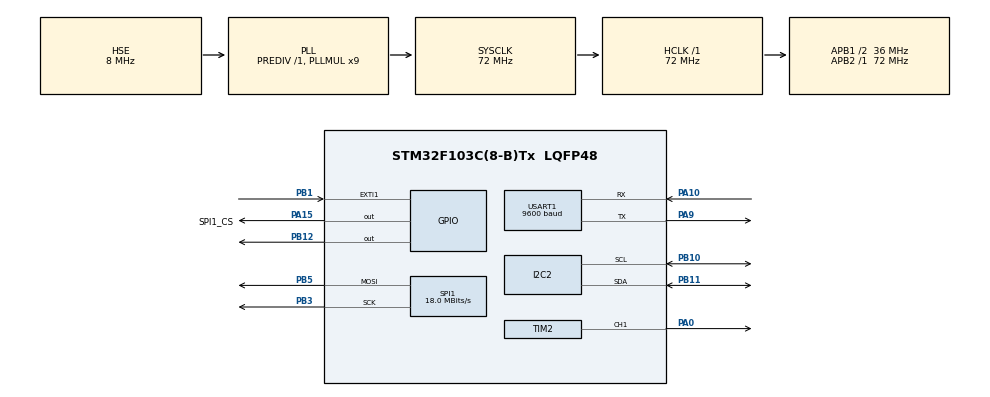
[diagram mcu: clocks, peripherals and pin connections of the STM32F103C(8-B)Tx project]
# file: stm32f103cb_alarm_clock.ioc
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Dma.Request0=TIM2_CH1
Dma.TIM2_CH1.0.Direction=DMA_MEMORY_TO_PERIPH
Dma.TIM2_CH1.0.Instance=DMA1_Channel5
Dma.TIM2_CH1.0.MemDataAlignment=DMA_MDATAALIGN_WORD
Dma.TIM2_CH1.0.MemInc=DMA_MINC_ENABLE
Dma.TIM2_CH1.0.Mode=DMA_NORMAL
Dma.TIM2_CH1.0.PeriphDataAlignment=DMA_PDATAALIGN_WORD
Dma.TIM2_CH1.0.PeriphInc=DMA_PINC_DISABLE
Dma.TIM2_CH1.0.Priority=DMA_PRIORITY_VERY_HIGH
Mcu.Family=STM32F1
Mcu.Name=STM32F103C(8-B)Tx
Mcu.Package=LQFP48
NVIC.DMA1_Channel5_IRQn=true\:0\:0\:false\:false\:true\:false\:true\:true
NVIC.EXTI1_IRQn=true\:0\:0\:false\:false\:true\:true\:true\:true
NVIC.PriorityGroup=NVIC_PRIORITYGROUP_4
NVIC.TIM3_IRQn=true\:0\:0\:false\:false\:true\:true\:true\:true
PA0-WKUP.Signal=S_TIM2_CH1_ETR
PA10.Mode=Asynchronous
PA10.Signal=USART1_RX
PA13.Mode=Serial_Wire
PA13.Signal=SYS_JTMS-SWDIO
PA14.Mode=Serial_Wire
PA14.Signal=SYS_JTCK-SWCLK
PA15.GPIO_Label=SPI1_CS
PA15.Signal=GPIO_Output
PA9.Mode=Asynchronous
PA9.Signal=USART1_TX
PB1.Signal=GPXTI1
PB10.Mode=I2C
PB10.Signal=I2C2_SCL
PB11.Mode=I2C
PB11.Signal=I2C2_SDA
PB12.Signal=GPIO_Output
PB3.Mode=TX_Only_Simplex_Unidirect_Master
PB3.Signal=SPI1_SCK
PB5.Mode=TX_Only_Simplex_Unidirect_Master
PB5.Signal=SPI1_MOSI
PC14-OSC32_IN.Mode=LSE-External-Oscillator
PC14-OSC32_IN.Signal=RCC_OSC32_IN
PC15-OSC32_OUT.Mode=LSE-External-Oscillator
PC15-OSC32_OUT.Signal=RCC_OSC32_OUT
PD0-OSC_IN.Mode=HSE-External-Oscillator
PD0-OSC_IN.Signal=RCC_OSC_IN
PD1-OSC_OUT.Mode=HSE-External-Oscillator
PD1-OSC_OUT.Signal=RCC_OSC_OUT
ProjectManager.HeapSize=0x200
ProjectManager.StackSize=0x400
ProjectManager.TargetToolchain=STM32CubeIDE
RCC.AHBFreq_Value=72000000
RCC.APB1CLKDivider=RCC_HCLK_DIV2
RCC.APB1Freq_Value=36000000
RCC.APB1TimFreq_Value=72000000
RCC.APB2Freq_Value=72000000
RCC.APB2TimFreq_Value=72000000
RCC.HCLKFreq_Value=72000000
RCC.PLLMUL=RCC_PLL_MUL9
RCC.PLLSourceVirtual=RCC_PLLSOURCE_HSE
RCC.SYSCLKFreq_VALUE=72000000
RCC.SYSCLKSource=RCC_SYSCLKSOURCE_PLLCLK
RCC.USBFreq_Value=72000000
SH.S_TIM2_CH1_ETR.0=TIM2_CH1,PWM Generation1 CH1
SPI1.BaudRatePrescaler=SPI_BAUDRATEPRESCALER_4
SPI1.CLKPhase=SPI_PHASE_2EDGE
SPI1.CLKPolarity=SPI_POLARITY_HIGH
SPI1.CalculateBaudRate=18.0 MBits/s
SPI1.DataSize=SPI_DATASIZE_8BIT
SPI1.Direction=SPI_DIRECTION_2LINES
SPI1.FirstBit=SPI_FIRSTBIT_MSB
SPI1.Mode=SPI_MODE_MASTER
SPI1.VirtualType=VM_MASTER
TIM1.Period=256
TIM1.Prescaler=1
TIM2.Channel-PWM\ Generation1\ CH1=TIM_CHANNEL_1
TIM2.Period=90-1
TIM3.Period=35999
TIM3.Prescaler=1
USART1.BaudRate=9600
USART1.Mode=MODE_TX_RX
USART1.VirtualMode=VM_ASYNC
VP_RTC_VS_RTC_Activate.Mode=RTC_Enabled
VP_RTC_VS_RTC_Calendar.Mode=RTC_Calendar
VP_TIM1_VS_ClockSourceINT.Mode=Internal
VP_TIM2_VS_ClockSourceINT.Mode=Internal
VP_TIM3_VS_ClockSourceINT.Mode=Internal
board=custom

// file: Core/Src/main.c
/* USER CODE BEGIN Header */
/**
  ******************************************************************************
  * @file           : main.c
  * @brief          : Main program body
  ******************************************************************************
  * @attention
  *
  * Copyright (c) 2025 STMicroelectronics.
  * All rights reserved.
  *
  * This software is licensed under terms that can be found in the LICENSE file
  * in the root directory of this software component.
  * If no LICENSE file comes with this software, it is provided AS-IS.
  *
  ******************************************************************************
  */
/* USER CODE END Header */
#include "main.h"

/* USER CODE BEGIN Includes */
#include "application.h"
/* USER CODE END Includes */

I2C_HandleTypeDef hi2c2;

RTC_HandleTypeDef hrtc;

SPI_HandleTypeDef hspi1;

TIM_HandleTypeDef htim1;
TIM_HandleTypeDef htim2;
TIM_HandleTypeDef htim3;
DMA_HandleTypeDef hdma_tim2_ch1;

UART_HandleTypeDef huart1;

void SystemClock_Config(void);
static void MX_GPIO_Init(void);
static void MX_DMA_Init(void);
static void MX_SPI1_Init(void);
static void MX_TIM2_Init(void);
static void MX_TIM1_Init(void);
static void MX_TIM3_Init(void);
static void MX_USART1_UART_Init(void);
static void MX_RTC_Init(void);
static void MX_I2C2_Init(void);

int main(void)
{

  /* MCU Configuration--------------------------------------------------------*/

  /* Reset of all peripherals, Initializes the Flash interface and the Systick. */
  HAL_Init();

  /* Configure the system clock */
  SystemClock_Config();

  /* Initialize all configured peripherals */
  MX_GPIO_Init();
  MX_DMA_Init();
  MX_SPI1_Init();
  MX_TIM2_Init();
  MX_TIM1_Init();
  MX_TIM3_Init();
  MX_USART1_UART_Init();
  MX_RTC_Init();
  MX_I2C2_Init();
  /* USER CODE BEGIN 2 */
  Application.init();
  /* USER CODE END 2 */

  /* Infinite loop */
  /* USER CODE BEGIN WHILE */
  while (1)
  {
	Application.run();
    /* USER CODE END WHILE */

  }
}

void SystemClock_Config(void)
{
  RCC_OscInitTypeDef RCC_OscInitStruct = {0};
  RCC_ClkInitTypeDef RCC_ClkInitStruct = {0};
  RCC_PeriphCLKInitTypeDef PeriphClkInit = {0};

  /** Initializes the RCC Oscillators according to the specified parameters
  * in the RCC_OscInitTypeDef structure.
  */
  RCC_OscInitStruct.OscillatorType = RCC_OSCILLATORTYPE_LSI|RCC_OSCILLATORTYPE_HSE;
  RCC_OscInitStruct.HSEState = RCC_HSE_ON;
  RCC_OscInitStruct.HSEPredivValue = RCC_HSE_PREDIV_DIV1;
  RCC_OscInitStruct.HSIState = RCC_HSI_ON;
  RCC_OscInitStruct.LSIState = RCC_LSI_ON;
  RCC_OscInitStruct.PLL.PLLState = RCC_PLL_ON;
  RCC_OscInitStruct.PLL.PLLSource = RCC_PLLSOURCE_HSE;
  RCC_OscInitStruct.PLL.PLLMUL = RCC_PLL_MUL9;
  if (HAL_RCC_OscConfig(&RCC_OscInitStruct) != HAL_OK)
  {
    Error_Handler();
  }

  /** Initializes the CPU, AHB and APB buses clocks
  */
  RCC_ClkInitStruct.ClockType = RCC_CLOCKTYPE_HCLK|RCC_CLOCKTYPE_SYSCLK
                              |RCC_CLOCKTYPE_PCLK1|RCC_CLOCKTYPE_PCLK2;
  RCC_ClkInitStruct.SYSCLKSource = RCC_SYSCLKSOURCE_PLLCLK;
  RCC_ClkInitStruct.AHBCLKDivider = RCC_SYSCLK_DIV1;
  RCC_ClkInitStruct.APB1CLKDivider = RCC_HCLK_DIV2;
  RCC_ClkInitStruct.APB2CLKDivider = RCC_HCLK_DIV1;

  if (HAL_RCC_ClockConfig(&RCC_ClkInitStruct, FLASH_LATENCY_2) != HAL_OK)
  {
    Error_Handler();
  }
  PeriphClkInit.PeriphClockSelection = RCC_PERIPHCLK_RTC;
  PeriphClkInit.RTCClockSelection = RCC_RTCCLKSOURCE_LSI;
  if (HAL_RCCEx_PeriphCLKConfig(&PeriphClkInit) != HAL_OK)
  {
    Error_Handler();
  }
}

static void MX_I2C2_Init(void)
{

  hi2c2.Instance = I2C2;
  hi2c2.Init.ClockSpeed = 100000;
  hi2c2.Init.DutyCycle = I2C_DUTYCYCLE_2;
  hi2c2.Init.OwnAddress1 = 0;
  hi2c2.Init.AddressingMode = I2C_ADDRESSINGMODE_7BIT;
  hi2c2.Init.DualAddressMode = I2C_DUALADDRESS_DISABLE;
  hi2c2.Init.OwnAddress2 = 0;
  hi2c2.Init.GeneralCallMode = I2C_GENERALCALL_DISABLE;
  hi2c2.Init.NoStretchMode = I2C_NOSTRETCH_DISABLE;
  if (HAL_I2C_Init(&hi2c2) != HAL_OK)
  {
    Error_Handler();
  }

}

static void MX_RTC_Init(void)
{

  RTC_TimeTypeDef sTime = {0};
  RTC_DateTypeDef DateToUpdate = {0};

  /** Initialize RTC Only
  */
  hrtc.Instance = RTC;
  hrtc.Init.AsynchPrediv = RTC_AUTO_1_SECOND;
  hrtc.Init.OutPut = RTC_OUTPUTSOURCE_ALARM;
  if (HAL_RTC_Init(&hrtc) != HAL_OK)
  {
    Error_Handler();
  }

  /** Initialize RTC and set the Time and Date
  */
  sTime.Hours = 0x0;
  sTime.Minutes = 0x0;
  sTime.Seconds = 0x0;

  if (HAL_RTC_SetTime(&hrtc, &sTime, RTC_FORMAT_BCD) != HAL_OK)
  {
    Error_Handler();
  }
  DateToUpdate.WeekDay = RTC_WEEKDAY_MONDAY;
  DateToUpdate.Month = RTC_MONTH_JANUARY;
  DateToUpdate.Date = 0x1;
  DateToUpdate.Year = 0x0;

  if (HAL_RTC_SetDate(&hrtc, &DateToUpdate, RTC_FORMAT_BCD) != HAL_OK)
  {
    Error_Handler();
  }

}

static void MX_SPI1_Init(void)
{

  /* SPI1 parameter configuration*/
  hspi1.Instance = SPI1;
  hspi1.Init.Mode = SPI_MODE_MASTER;
  hspi1.Init.Direction = SPI_DIRECTION_2LINES;
  hspi1.Init.DataSize = SPI_DATASIZE_8BIT;
  hspi1.Init.CLKPolarity = SPI_POLARITY_HIGH;
  hspi1.Init.CLKPhase = SPI_PHASE_2EDGE;
  hspi1.Init.NSS = SPI_NSS_SOFT;
  hspi1.Init.BaudRatePrescaler = SPI_BAUDRATEPRESCALER_4;
  hspi1.Init.FirstBit = SPI_FIRSTBIT_MSB;
  hspi1.Init.TIMode = SPI_TIMODE_DISABLE;
  hspi1.Init.CRCCalculation = SPI_CRCCALCULATION_DISABLE;
  hspi1.Init.CRCPolynomial = 10;
  if (HAL_SPI_Init(&hspi1) != HAL_OK)
  {
    Error_Handler();
  }

}

static void MX_TIM1_Init(void)
{

  TIM_ClockConfigTypeDef sClockSourceConfig = {0};
  TIM_MasterConfigTypeDef sMasterConfig = {0};

  htim1.Instance = TIM1;
  htim1.Init.Prescaler = 1;
  htim1.Init.CounterMode = TIM_COUNTERMODE_UP;
  htim1.Init.Period = 256;
  htim1.Init.ClockDivision = TIM_CLOCKDIVISION_DIV1;
  htim1.Init.RepetitionCounter = 0;
  htim1.Init.AutoReloadPreload = TIM_AUTORELOAD_PRELOAD_DISABLE;
  if (HAL_TIM_Base_Init(&htim1) != HAL_OK)
  {
    Error_Handler();
  }
  sClockSourceConfig.ClockSource = TIM_CLOCKSOURCE_INTERNAL;
  if (HAL_TIM_ConfigClockSource(&htim1, &sClockSourceConfig) != HAL_OK)
  {
    Error_Handler();
  }
  sMasterConfig.MasterOutputTrigger = TIM_TRGO_RESET;
  sMasterConfig.MasterSlaveMode = TIM_MASTERSLAVEMODE_DISABLE;
  if (HAL_TIMEx_MasterConfigSynchronization(&htim1, &sMasterConfig) != HAL_OK)
  {
    Error_Handler();
  }

}

static void MX_TIM2_Init(void)
{

  TIM_ClockConfigTypeDef sClockSourceConfig = {0};
  TIM_MasterConfigTypeDef sMasterConfig = {0};
  TIM_OC_InitTypeDef sConfigOC = {0};

  htim2.Instance = TIM2;
  htim2.Init.Prescaler = 0;
  htim2.Init.CounterMode = TIM_COUNTERMODE_UP;
  htim2.Init.Period = 90-1;
  htim2.Init.ClockDivision = TIM_CLOCKDIVISION_DIV1;
  htim2.Init.AutoReloadPreload = TIM_AUTORELOAD_PRELOAD_DISABLE;
  if (HAL_TIM_Base_Init(&htim2) != HAL_OK)
  {
    Error_Handler();
  }
  sClockSourceConfig.ClockSource = TIM_CLOCKSOURCE_INTERNAL;
  if (HAL_TIM_ConfigClockSource(&htim2, &sClockSourceConfig) != HAL_OK)
  {
    Error_Handler();
  }
  if (HAL_TIM_PWM_Init(&htim2) != HAL_OK)
  {
    Error_Handler();
  }
  sMasterConfig.MasterOutputTrigger = TIM_TRGO_RESET;
  sMasterConfig.MasterSlaveMode = TIM_MASTERSLAVEMODE_DISABLE;
  if (HAL_TIMEx_MasterConfigSynchronization(&htim2, &sMasterConfig) != HAL_OK)
  {
    Error_Handler();
  }
  sConfigOC.OCMode = TIM_OCMODE_PWM1;
  sConfigOC.Pulse = 0;
  sConfigOC.OCPolarity = TIM_OCPOLARITY_HIGH;
  sConfigOC.OCFastMode = TIM_OCFAST_DISABLE;
  if (HAL_TIM_PWM_ConfigChannel(&htim2, &sConfigOC, TIM_CHANNEL_1) != HAL_OK)
  {
    Error_Handler();
  }
  HAL_TIM_MspPostInit(&htim2);

}

static void MX_TIM3_Init(void)
{

  TIM_ClockConfigTypeDef sClockSourceConfig = {0};
  TIM_MasterConfigTypeDef sMasterConfig = {0};

  htim3.Instance = TIM3;
  htim3.Init.Prescaler = 1;
  htim3.Init.CounterMode = TIM_COUNTERMODE_UP;
  htim3.Init.Period = 35999;
  htim3.Init.ClockDivision = TIM_CLOCKDIVISION_DIV1;
  htim3.Init.AutoReloadPreload = TIM_AUTORELOAD_PRELOAD_DISABLE;
  if (HAL_TIM_Base_Init(&htim3) != HAL_OK)
  {
    Error_Handler();
  }
  sClockSourceConfig.ClockSource = TIM_CLOCKSOURCE_INTERNAL;
  if (HAL_TIM_ConfigClockSource(&htim3, &sClockSourceConfig) != HAL_OK)
  {
    Error_Handler();
  }
  sMasterConfig.MasterOutputTrigger = TIM_TRGO_RESET;
  sMasterConfig.MasterSlaveMode = TIM_MASTERSLAVEMODE_DISABLE;
  if (HAL_TIMEx_MasterConfigSynchronization(&htim3, &sMasterConfig) != HAL_OK)
  {
    Error_Handler();
  }

}

static void MX_USART1_UART_Init(void)
{

  huart1.Instance = USART1;
  huart1.Init.BaudRate = 9600;
  huart1.Init.WordLength = UART_WORDLENGTH_8B;
  huart1.Init.StopBits = UART_STOPBITS_1;
  huart1.Init.Parity = UART_PARITY_NONE;
  huart1.Init.Mode = UART_MODE_TX_RX;
  huart1.Init.HwFlowCtl = UART_HWCONTROL_NONE;
  huart1.Init.OverSampling = UART_OVERSAMPLING_16;
  if (HAL_UART_Init(&huart1) != HAL_OK)
  {
    Error_Handler();
  }

}

static void MX_DMA_Init(void)
{

  /* DMA controller clock enable */
  __HAL_RCC_DMA1_CLK_ENABLE();

  /* DMA interrupt init */
  /* DMA1_Channel5_IRQn interrupt configuration */
  HAL_NVIC_SetPriority(DMA1_Channel5_IRQn, 0, 0);
  HAL_NVIC_EnableIRQ(DMA1_Channel5_IRQn);

}

static void MX_GPIO_Init(void)
{
  GPIO_InitTypeDef GPIO_InitStruct = {0};

  /* GPIO Ports Clock Enable */
  __HAL_RCC_GPIOC_CLK_ENABLE();
  __HAL_RCC_GPIOD_CLK_ENABLE();
  __HAL_RCC_GPIOA_CLK_ENABLE();
  __HAL_RCC_GPIOB_CLK_ENABLE();

  /*Configure GPIO pin Output Level */
  HAL_GPIO_WritePin(GPIOB, GPIO_PIN_12, GPIO_PIN_RESET);

  /*Configure GPIO pin Output Level */
  HAL_GPIO_WritePin(SPI1_CS_GPIO_Port, SPI1_CS_Pin, GPIO_PIN_RESET);

  /*Configure GPIO pin : PB1 */
  GPIO_InitStruct.Pin = GPIO_PIN_1;
  GPIO_InitStruct.Mode = GPIO_MODE_IT_RISING;
  GPIO_InitStruct.Pull = GPIO_NOPULL;
  HAL_GPIO_Init(GPIOB, &GPIO_InitStruct);

  /*Configure GPIO pin : PB12 */
  GPIO_InitStruct.Pin = GPIO_PIN_12;
  GPIO_InitStruct.Mode = GPIO_MODE_OUTPUT_PP;
  GPIO_InitStruct.Pull = GPIO_NOPULL;
  GPIO_InitStruct.Speed = GPIO_SPEED_FREQ_LOW;
  HAL_GPIO_Init(GPIOB, &GPIO_InitStruct);

  /*Configure GPIO pin : SPI1_CS_Pin */
  GPIO_InitStruct.Pin = SPI1_CS_Pin;
  GPIO_InitStruct.Mode = GPIO_MODE_OUTPUT_PP;
  GPIO_InitStruct.Pull = GPIO_NOPULL;
  GPIO_InitStruct.Speed = GPIO_SPEED_FREQ_LOW;
  HAL_GPIO_Init(SPI1_CS_GPIO_Port, &GPIO_InitStruct);

  /* EXTI interrupt init*/
  HAL_NVIC_SetPriority(EXTI1_IRQn, 0, 0);
  HAL_NVIC_EnableIRQ(EXTI1_IRQn);

}

void Error_Handler(void)
{
  __disable_irq();
  while (1)
  {
  }
}
